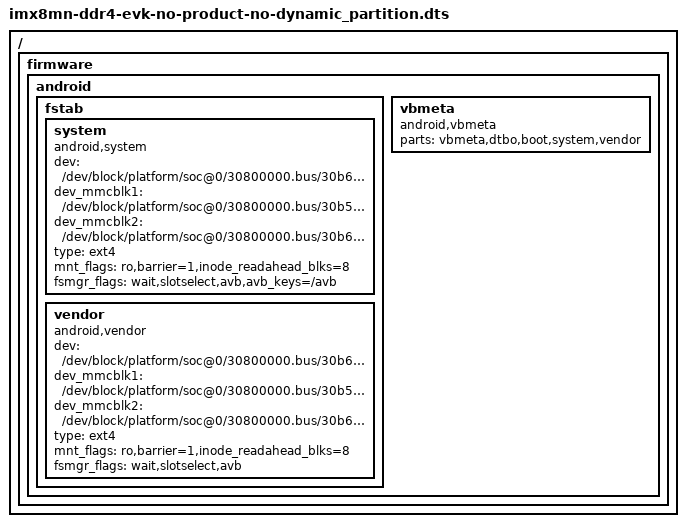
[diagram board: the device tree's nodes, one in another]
/*
 * Copyright 2019 NXP
 *
 * This program is free software; you can redistribute it and/or
 * modify it under the terms of the GNU General Public License
 * as published by the Free Software Foundation; either version 2
 * of the License, or (at your option) any later version.
 *
 * This program is distributed in the hope that it will be useful,
 * but WITHOUT ANY WARRANTY; without even the implied warranty of
 * MERCHANTABILITY or FITNESS FOR A PARTICULAR PURPOSE.  See the
 * GNU General Public License for more details.
 */

/dts-v1/;
#include "imx8mn-ddr4-evk.dts"

/ {
	firmware {
		android {
			fstab {
				/delete-node/ product;
				system {
					compatible = "android,system";
					/* default emmc node used for GSI */
					dev = "/dev/block/platform/soc@0/30800000.bus/30b60000.mmc/by-name/system";
					/* sd card node which used if androidboot.boot_device_root=mmcblk1 */
					dev_mmcblk1 = "/dev/block/platform/soc@0/30800000.bus/30b50000.mmc/by-name/system";
					/* emmc node which used if androidboot.boot_device_root=mmcblk2 */
					dev_mmcblk2 = "/dev/block/platform/soc@0/30800000.bus/30b60000.mmc/by-name/system";
					type = "ext4";
					mnt_flags = "ro,barrier=1,inode_readahead_blks=8";
					fsmgr_flags = "wait,slotselect,avb,avb_keys=/avb";
				};
				vendor {
					compatible = "android,vendor";
					/* default emmc node used for GSI */
					dev = "/dev/block/platform/soc@0/30800000.bus/30b60000.mmc/by-name/vendor";
					/* sd card node which used if androidboot.boot_device_root=mmcblk1 */
					dev_mmcblk1 = "/dev/block/platform/soc@0/30800000.bus/30b50000.mmc/by-name/vendor";
					/* emmc node which used if androidboot.boot_device_root=mmcblk2 */
					dev_mmcblk2 = "/dev/block/platform/soc@0/30800000.bus/30b60000.mmc/by-name/vendor";
					type = "ext4";
					mnt_flags = "ro,barrier=1,inode_readahead_blks=8";
					fsmgr_flags = "wait,slotselect,avb";
				};
			};
			vbmeta {
				/*we need use FirstStageMountVBootV2 if we enable avb*/
				compatible = "android,vbmeta";
				/*parts means the partition witch can be mount in first stage*/
				parts = "vbmeta,dtbo,boot,system,vendor";
			};
		};
	};
};
